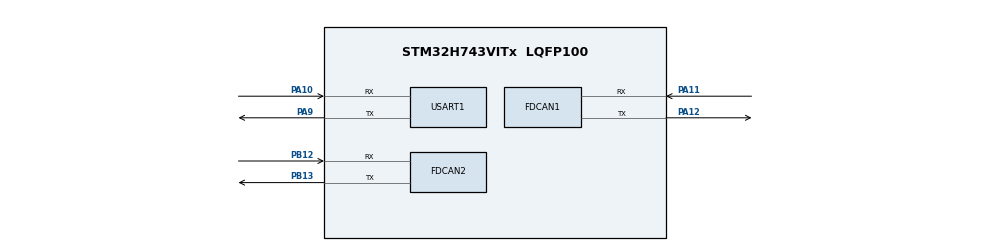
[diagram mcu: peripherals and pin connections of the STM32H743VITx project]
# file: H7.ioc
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CORTEX_M7.default_mode_Activation=1
FDCAN1.CalculateBaudRateNominal=249999
FDCAN1.CalculateTimeBitNominal=4000
FDCAN1.CalculateTimeQuantumNominal=166.66666666666669
FDCAN1.DataPrescaler=3
FDCAN1.DataTimeSeg1=7
FDCAN1.DataTimeSeg2=2
FDCAN1.FrameFormat=FDCAN_FRAME_FD_BRS
FDCAN1.Mode=FDCAN_MODE_NORMAL
FDCAN1.NominalPrescaler=10
FDCAN1.NominalTimeSeg1=20
FDCAN1.NominalTimeSeg2=3
FDCAN1.RxFifo0ElmtsNbr=2
FDCAN1.TxFifoQueueElmtsNbr=2
FDCAN2.CalculateBaudRateNominal=499999
FDCAN2.CalculateTimeBitNominal=2000
FDCAN2.CalculateTimeQuantumNominal=83.33333333333334
FDCAN2.Mode=FDCAN_MODE_INTERNAL_LOOPBACK
FDCAN2.NominalPrescaler=5
FDCAN2.NominalTimeSeg1=13
FDCAN2.NominalTimeSeg2=10
FDCAN2.RxFifo0ElmtsNbr=2
Mcu.Family=STM32H7
Mcu.Name=STM32H743VITx
Mcu.Package=LQFP100
NVIC.FDCAN1_IT0_IRQn=true\:0\:0\:false\:false\:true\:true\:true\:true
NVIC.FDCAN2_IT0_IRQn=true\:0\:0\:false\:false\:true\:true\:true\:true
NVIC.PriorityGroup=NVIC_PRIORITYGROUP_4
PA10.Mode=Asynchronous
PA10.Signal=USART1_RX
PA11.Mode=FDCAN_Activate
PA11.Signal=FDCAN1_RX
PA12.Mode=FDCAN_Activate
PA12.Signal=FDCAN1_TX
PA9.Mode=Asynchronous
PA9.Signal=USART1_TX
PB12.Mode=FDCAN_Activate
PB12.Signal=FDCAN2_RX
PB13.Mode=FDCAN_Activate
PB13.Signal=FDCAN2_TX
PC14-OSC32_IN\ (OSC32_IN).Mode=LSE-External-Oscillator
PC14-OSC32_IN\ (OSC32_IN).Signal=RCC_OSC32_IN
PC15-OSC32_OUT\ (OSC32_OUT).Mode=LSE-External-Oscillator
PC15-OSC32_OUT\ (OSC32_OUT).Signal=RCC_OSC32_OUT
PH0-OSC_IN\ (PH0).Mode=HSE-External-Oscillator
PH0-OSC_IN\ (PH0).Signal=RCC_OSC_IN
PH1-OSC_OUT\ (PH1).Mode=HSE-External-Oscillator
PH1-OSC_OUT\ (PH1).Signal=RCC_OSC_OUT
ProjectManager.HeapSize=0x200
ProjectManager.StackSize=0x400
ProjectManager.TargetToolchain=MDK-ARM V5.32
RCC.ADCFreq_Value=50390625
RCC.APB1Freq_Value=60000000
RCC.APB2Freq_Value=60000000
RCC.APB3Freq_Value=60000000
RCC.APB4Freq_Value=60000000
RCC.CortexFreq_Value=240000000
RCC.D1PPRE=RCC_APB3_DIV2
RCC.D2PPRE1=RCC_APB1_DIV2
RCC.D2PPRE2=RCC_APB2_DIV2
RCC.D3PPRE=RCC_APB4_DIV2
RCC.DIVM1=5
RCC.DIVN1=96
RCC.DIVQ1=8
RCC.HCLKFreq_Value=120000000
RCC.HPRE=RCC_HCLK_DIV2
RCC.PLLFRACN=0
RCC.PLLSourceVirtual=RCC_PLLSOURCE_HSE
RCC.SYSCLKFreq_VALUE=240000000
RCC.SYSCLKSource=RCC_SYSCLKSOURCE_PLLCLK
RCC.USBFreq_Value=60000000
USART1.VirtualMode-Asynchronous=VM_ASYNC
VP_MEMORYMAP_VS_MEMORYMAP.Mode=CurAppReg
board=custom

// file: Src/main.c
/* USER CODE BEGIN Header */
/**
  ******************************************************************************
  * @file           : main.c
  * @brief          : Main program body
  ******************************************************************************
  * @attention
  *
  * Copyright (c) 2026 STMicroelectronics.
  * All rights reserved.
  *
  * This software is licensed under terms that can be found in the LICENSE file
  * in the root directory of this software component.
  * If no LICENSE file comes with this software, it is provided AS-IS.
  *
  ******************************************************************************
  */
/* USER CODE END Header */
#include "main.h"

/* USER CODE BEGIN Includes */
#include "bsp_can.h"
#include "can_app.h"
/* USER CODE END Includes */

FDCAN_HandleTypeDef hfdcan1;
FDCAN_HandleTypeDef hfdcan2;

UART_HandleTypeDef huart1;

void SystemClock_Config(void);
static void MPU_Config(void);
static void MX_GPIO_Init(void);
static void MX_FDCAN1_Init(void);
static void MX_FDCAN2_Init(void);
static void MX_USART1_UART_Init(void);

/* USER CODE BEGIN 0 */
#include <stdio.h>

int fputc(int ch, FILE *f)
{
    HAL_UART_Transmit(&huart1, (uint8_t *)&ch, 1, 100);
    return ch;
}
/* USER CODE END 0 */

int main(void)
{

  /* MPU Configuration--------------------------------------------------------*/
  MPU_Config();

  /* MCU Configuration--------------------------------------------------------*/

  /* Reset of all peripherals, Initializes the Flash interface and the Systick. */
  HAL_Init();

  /* Configure the system clock */
  SystemClock_Config();

  /* Initialize all configured peripherals */
  MX_GPIO_Init();
  MX_FDCAN1_Init();
  MX_FDCAN2_Init();
  MX_USART1_UART_Init();
  /* USER CODE BEGIN 2 */
  APP_CAN_Init();
  bsp_InitCan1();
  bsp_InitCan2();
  /* USER CODE END 2 */

  /* Infinite loop */
  /* USER CODE BEGIN WHILE */
  uint8_t test_data[8] = {0x01, 0x02, 0x03, 0x04, 0x05, 0x06, 0x07, 0x08};
  while (1)
  {
	APP_CAN_Task_10ms();
    HAL_Delay(10); // 10ms
    /* USER CODE END WHILE */

  }
}

void SystemClock_Config(void)
{
  RCC_OscInitTypeDef RCC_OscInitStruct = {0};
  RCC_ClkInitTypeDef RCC_ClkInitStruct = {0};

  /** Supply configuration update enable
  */
  HAL_PWREx_ConfigSupply(PWR_LDO_SUPPLY);

  /** Configure the main internal regulator output voltage
  */
  __HAL_PWR_VOLTAGESCALING_CONFIG(PWR_REGULATOR_VOLTAGE_SCALE2);

  while(!__HAL_PWR_GET_FLAG(PWR_FLAG_VOSRDY)) {}

  /** Initializes the RCC Oscillators according to the specified parameters
  * in the RCC_OscInitTypeDef structure.
  */
  RCC_OscInitStruct.OscillatorType = RCC_OSCILLATORTYPE_HSE;
  RCC_OscInitStruct.HSEState = RCC_HSE_ON;
  RCC_OscInitStruct.PLL.PLLState = RCC_PLL_ON;
  RCC_OscInitStruct.PLL.PLLSource = RCC_PLLSOURCE_HSE;
  RCC_OscInitStruct.PLL.PLLM = 5;
  RCC_OscInitStruct.PLL.PLLN = 96;
  RCC_OscInitStruct.PLL.PLLP = 2;
  RCC_OscInitStruct.PLL.PLLQ = 8;
  RCC_OscInitStruct.PLL.PLLR = 2;
  RCC_OscInitStruct.PLL.PLLRGE = RCC_PLL1VCIRANGE_2;
  RCC_OscInitStruct.PLL.PLLVCOSEL = RCC_PLL1VCOWIDE;
  RCC_OscInitStruct.PLL.PLLFRACN = 0;
  if (HAL_RCC_OscConfig(&RCC_OscInitStruct) != HAL_OK)
  {
    Error_Handler();
  }

  /** Initializes the CPU, AHB and APB buses clocks
  */
  RCC_ClkInitStruct.ClockType = RCC_CLOCKTYPE_HCLK|RCC_CLOCKTYPE_SYSCLK
                              |RCC_CLOCKTYPE_PCLK1|RCC_CLOCKTYPE_PCLK2
                              |RCC_CLOCKTYPE_D3PCLK1|RCC_CLOCKTYPE_D1PCLK1;
  RCC_ClkInitStruct.SYSCLKSource = RCC_SYSCLKSOURCE_PLLCLK;
  RCC_ClkInitStruct.SYSCLKDivider = RCC_SYSCLK_DIV1;
  RCC_ClkInitStruct.AHBCLKDivider = RCC_HCLK_DIV2;
  RCC_ClkInitStruct.APB3CLKDivider = RCC_APB3_DIV2;
  RCC_ClkInitStruct.APB1CLKDivider = RCC_APB1_DIV2;
  RCC_ClkInitStruct.APB2CLKDivider = RCC_APB2_DIV2;
  RCC_ClkInitStruct.APB4CLKDivider = RCC_APB4_DIV2;

  if (HAL_RCC_ClockConfig(&RCC_ClkInitStruct, FLASH_LATENCY_2) != HAL_OK)
  {
    Error_Handler();
  }

	/* ↓↓↓ 加上这三行！强制把 FDCAN 时钟源切到 PLL1Q (60MHz) ↓↓↓ */
  RCC_PeriphCLKInitTypeDef PeriphClkInit = {0};
  PeriphClkInit.PeriphClockSelection = RCC_PERIPHCLK_FDCAN;
  PeriphClkInit.FdcanClockSelection = RCC_FDCANCLKSOURCE_PLL;
  HAL_RCCEx_PeriphCLKConfig(&PeriphClkInit);
}

static void MX_FDCAN1_Init(void)
{

  hfdcan1.Instance = FDCAN1;
  hfdcan1.Init.FrameFormat = FDCAN_FRAME_FD_BRS;
  hfdcan1.Init.Mode = FDCAN_MODE_NORMAL;
  hfdcan1.Init.AutoRetransmission = DISABLE;
  hfdcan1.Init.TransmitPause = DISABLE;
  hfdcan1.Init.ProtocolException = DISABLE;
  hfdcan1.Init.NominalPrescaler = 10;
  hfdcan1.Init.NominalSyncJumpWidth = 1;
  hfdcan1.Init.NominalTimeSeg1 = 20;
  hfdcan1.Init.NominalTimeSeg2 = 3;
  hfdcan1.Init.DataPrescaler = 3;
  hfdcan1.Init.DataSyncJumpWidth = 1;
  hfdcan1.Init.DataTimeSeg1 = 7;
  hfdcan1.Init.DataTimeSeg2 = 2;
  hfdcan1.Init.MessageRAMOffset = 0;
  hfdcan1.Init.StdFiltersNbr = 0;
  hfdcan1.Init.ExtFiltersNbr = 0;
  hfdcan1.Init.RxFifo0ElmtsNbr = 2;
  hfdcan1.Init.RxFifo0ElmtSize = FDCAN_DATA_BYTES_8;
  hfdcan1.Init.RxFifo1ElmtsNbr = 0;
  hfdcan1.Init.RxFifo1ElmtSize = FDCAN_DATA_BYTES_8;
  hfdcan1.Init.RxBuffersNbr = 0;
  hfdcan1.Init.RxBufferSize = FDCAN_DATA_BYTES_8;
  hfdcan1.Init.TxEventsNbr = 0;
  hfdcan1.Init.TxBuffersNbr = 0;
  hfdcan1.Init.TxFifoQueueElmtsNbr = 2;
  hfdcan1.Init.TxFifoQueueMode = FDCAN_TX_FIFO_OPERATION;
  hfdcan1.Init.TxElmtSize = FDCAN_DATA_BYTES_8;
  if (HAL_FDCAN_Init(&hfdcan1) != HAL_OK)
  {
    Error_Handler();
  }

}

static void MX_FDCAN2_Init(void)
{

  hfdcan2.Instance = FDCAN2;
  hfdcan2.Init.FrameFormat = FDCAN_FRAME_CLASSIC;
  hfdcan2.Init.Mode = FDCAN_MODE_INTERNAL_LOOPBACK;
  hfdcan2.Init.AutoRetransmission = DISABLE;
  hfdcan2.Init.TransmitPause = DISABLE;
  hfdcan2.Init.ProtocolException = DISABLE;
  hfdcan2.Init.NominalPrescaler = 5;
  hfdcan2.Init.NominalSyncJumpWidth = 1;
  hfdcan2.Init.NominalTimeSeg1 = 13;
  hfdcan2.Init.NominalTimeSeg2 = 10;
  hfdcan2.Init.DataPrescaler = 1;
  hfdcan2.Init.DataSyncJumpWidth = 1;
  hfdcan2.Init.DataTimeSeg1 = 1;
  hfdcan2.Init.DataTimeSeg2 = 1;
  hfdcan2.Init.MessageRAMOffset = 0;
  hfdcan2.Init.StdFiltersNbr = 0;
  hfdcan2.Init.ExtFiltersNbr = 0;
  hfdcan2.Init.RxFifo0ElmtsNbr = 2;
  hfdcan2.Init.RxFifo0ElmtSize = FDCAN_DATA_BYTES_8;
  hfdcan2.Init.RxFifo1ElmtsNbr = 0;
  hfdcan2.Init.RxFifo1ElmtSize = FDCAN_DATA_BYTES_8;
  hfdcan2.Init.RxBuffersNbr = 0;
  hfdcan2.Init.RxBufferSize = FDCAN_DATA_BYTES_8;
  hfdcan2.Init.TxEventsNbr = 0;
  hfdcan2.Init.TxBuffersNbr = 0;
  hfdcan2.Init.TxFifoQueueElmtsNbr = 0;
  hfdcan2.Init.TxFifoQueueMode = FDCAN_TX_FIFO_OPERATION;
  hfdcan2.Init.TxElmtSize = FDCAN_DATA_BYTES_8;
  if (HAL_FDCAN_Init(&hfdcan2) != HAL_OK)
  {
    Error_Handler();
  }

}

static void MX_USART1_UART_Init(void)
{

  huart1.Instance = USART1;
  huart1.Init.BaudRate = 115200;
  huart1.Init.WordLength = UART_WORDLENGTH_8B;
  huart1.Init.StopBits = UART_STOPBITS_1;
  huart1.Init.Parity = UART_PARITY_NONE;
  huart1.Init.Mode = UART_MODE_TX_RX;
  huart1.Init.HwFlowCtl = UART_HWCONTROL_NONE;
  huart1.Init.OverSampling = UART_OVERSAMPLING_16;
  huart1.Init.OneBitSampling = UART_ONE_BIT_SAMPLE_DISABLE;
  huart1.Init.ClockPrescaler = UART_PRESCALER_DIV1;
  huart1.AdvancedInit.AdvFeatureInit = UART_ADVFEATURE_NO_INIT;
  if (HAL_UART_Init(&huart1) != HAL_OK)
  {
    Error_Handler();
  }
  if (HAL_UARTEx_SetTxFifoThreshold(&huart1, UART_TXFIFO_THRESHOLD_1_8) != HAL_OK)
  {
    Error_Handler();
  }
  if (HAL_UARTEx_SetRxFifoThreshold(&huart1, UART_RXFIFO_THRESHOLD_1_8) != HAL_OK)
  {
    Error_Handler();
  }
  if (HAL_UARTEx_DisableFifoMode(&huart1) != HAL_OK)
  {
    Error_Handler();
  }

}

static void MX_GPIO_Init(void)
{

  /* GPIO Ports Clock Enable */
  __HAL_RCC_GPIOC_CLK_ENABLE();
  __HAL_RCC_GPIOH_CLK_ENABLE();
  __HAL_RCC_GPIOB_CLK_ENABLE();
  __HAL_RCC_GPIOA_CLK_ENABLE();

}

 /* MPU Configuration */

void MPU_Config(void)
{
  MPU_Region_InitTypeDef MPU_InitStruct = {0};

  /* Disables the MPU */
  HAL_MPU_Disable();

  /** Initializes and configures the Region and the memory to be protected
  */
  MPU_InitStruct.Enable = MPU_REGION_ENABLE;
  MPU_InitStruct.Number = MPU_REGION_NUMBER0;
  MPU_InitStruct.BaseAddress = 0x0;
  MPU_InitStruct.Size = MPU_REGION_SIZE_4GB;
  MPU_InitStruct.SubRegionDisable = 0x87;
  MPU_InitStruct.TypeExtField = MPU_TEX_LEVEL0;
  MPU_InitStruct.AccessPermission = MPU_REGION_NO_ACCESS;
  MPU_InitStruct.DisableExec = MPU_INSTRUCTION_ACCESS_DISABLE;
  MPU_InitStruct.IsShareable = MPU_ACCESS_SHAREABLE;
  MPU_InitStruct.IsCacheable = MPU_ACCESS_NOT_CACHEABLE;
  MPU_InitStruct.IsBufferable = MPU_ACCESS_NOT_BUFFERABLE;

  HAL_MPU_ConfigRegion(&MPU_InitStruct);
  /* Enables the MPU */
  HAL_MPU_Enable(MPU_PRIVILEGED_DEFAULT);

}

void Error_Handler(void)
{
  __disable_irq();
  while (1)
  {
  }
}
